# STM32F7x2 register map
File version: 1.3
CPU: CM7 r0p1, little endian, MPU, FPU, 4 interrupt priority bits
Registers are 32-bit, read-write, reset 0x0 unless marked. A register's access mark holds for its fields unless they carry their own. Offsets are from the block's base; [hi:lo] are bit positions; {n}, {i} and the like mark numbered series.

## STK — SysTick timer
Base 0xE000E010
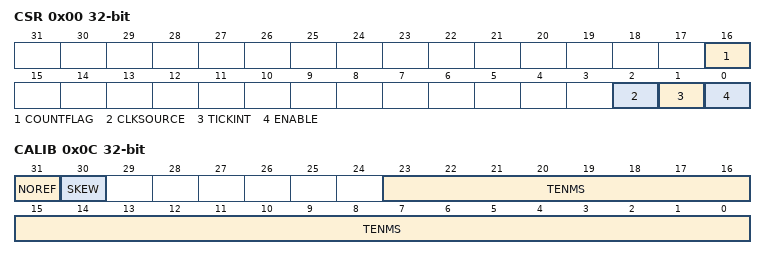
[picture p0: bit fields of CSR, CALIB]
0x00 CSR — SysTick control and status register
  [16] COUNTFLAG
  [2] CLKSOURCE — Clock source selection
  [1] TICKINT — SysTick exception request enable
  [0] ENABLE — Counter enable
0x04 RVR — SysTick reload value register
  [23:0] RELOAD — RELOAD value
0x08 CVR — SysTick current value register
  [23:0] CURRENT — Current counter value
0x0C CALIB — SysTick calibration value register
  [31] NOREF — NOREF flag. Reads as zero
  [30] SKEW — SKEW flag: Indicates whether the TENMS value is exact
  [23:0] TENMS — Calibration value

## NVIC_STIR — Nested vectored interrupt controller
Base 0xE000EF00
0x00 STIR — Software trigger interrupt register
  [8:0] INTID — Software generated interrupt ID

## FPU_CPACR — Floating point unit CPACR
Base 0xE000ED88
0x00 CPACR — Coprocessor access control register
  [23:20] CP

## SCB_ACTRL — System control block ACTLR
Base 0xE000E008
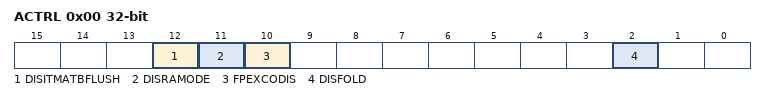
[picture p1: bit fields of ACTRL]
0x00 ACTRL — Auxiliary control register
  [12] DISITMATBFLUSH, [11] DISRAMODE, [10] FPEXCODIS, [2] DISFOLD

## FPU — Floting point unit
Base 0xE000EF34
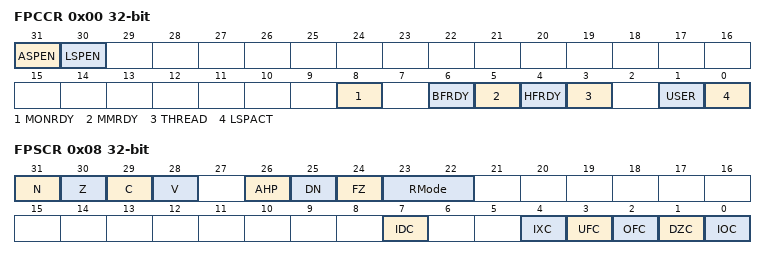
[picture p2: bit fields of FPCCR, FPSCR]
0x00 FPCCR — Floating-point context control register
  [31] ASPEN, [30] LSPEN, [8] MONRDY, [6] BFRDY, [5] MMRDY, [4] HFRDY, [3] THREAD, [1] USER, [0] LSPACT
0x04 FPCAR — Floating-point context address register
  [31:3] ADDRESS — Location of unpopulated floating-point
0x08 FPSCR — Floating-point status control register
  [31] N — Negative condition code flag
  [30] Z — Zero condition code flag
  [29] C — Carry condition code flag
  [28] V — Overflow condition code flag
  [26] AHP — Alternative half-precision control bit
  [25] DN — Default NaN mode control bit
  [24] FZ — Flush-to-zero mode control bit:
  [23:22] RMode — Rounding Mode control field
  [7] IDC — Input denormal cumulative exception bit.
  [4] IXC — Inexact cumulative exception bit
  [3] UFC — Underflow cumulative exception bit
  [2] OFC — Overflow cumulative exception bit
  [1] DZC — Division by zero cumulative exception bit.
  [0] IOC — Invalid operation cumulative exception bit

## PF — Processor features
Base 0xE000ED78
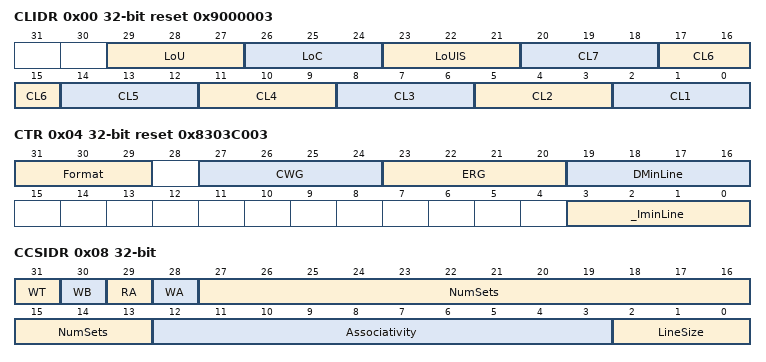
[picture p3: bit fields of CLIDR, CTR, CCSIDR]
0x00 CLIDR ro reset 0x9000003 — Cache Level ID register
  [29:27] LoU, [26:24] LoC, [23:21] LoUIS, [3n-1:3n-3] CL{n} (n=1..7)
0x04 CTR ro reset 0x8303C003 — Cache Type register
  [31:29] Format, [27:24] CWG, [23:20] ERG, [19:16] DMinLine, [3:0] _IminLine
0x08 CCSIDR ro — Cache Size ID register
  [31] WT, [30] WB, [29] RA, [28] WA, [27:13] NumSets, [12:3] Associativity, [2:0] LineSize

## AC — Access control
Base 0xE000EF90
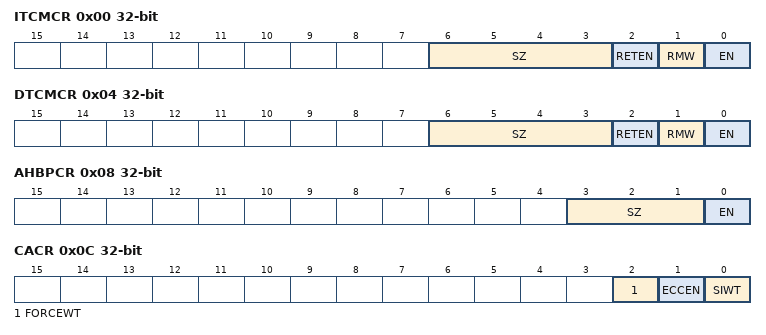
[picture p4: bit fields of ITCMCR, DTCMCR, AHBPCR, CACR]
0x00 ITCMCR — Instruction and Data Tightly-Coupled Memory Control Registers
  [6:3] SZ, [2] RETEN, [1] RMW, [0] EN
0x04 DTCMCR — Instruction and Data Tightly-Coupled Memory Control Registers
  [6:3] SZ, [2] RETEN, [1] RMW, [0] EN
0x08 AHBPCR — AHBP Control register
  [3:1] SZ, [0] EN
0x0C CACR — Auxiliary Cache Control register
  [2] FORCEWT, [1] ECCEN, [0] SIWT
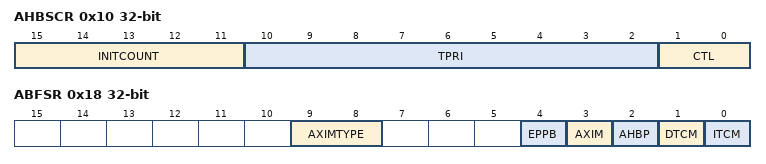
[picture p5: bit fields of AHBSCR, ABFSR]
0x10 AHBSCR — AHB Slave Control register
  [15:11] INITCOUNT, [10:2] TPRI, [1:0] CTL
0x18 ABFSR — Auxiliary Bus Fault Status register
  [9:8] AXIMTYPE, [4] EPPB, [3] AXIM, [2] AHBP, [1] DTCM, [0] ITCM

## AES — Advanced encryption standard hardware accelerator 1
Base 0x50060000
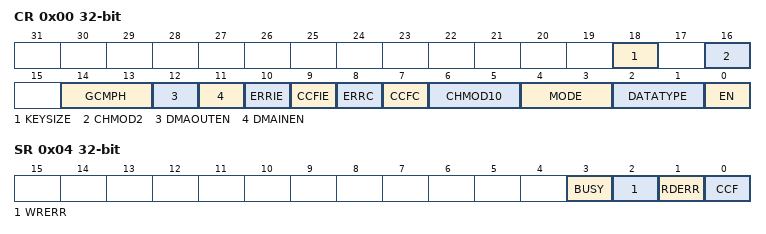
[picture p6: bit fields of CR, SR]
0x00 CR — control register
  [18] KEYSIZE — Key size selection
  [16] CHMOD2 — AES chaining mode Bit2
  [14:13] GCMPH — Used only for GCM, CCM and GMAC algorithms and has no effect when other algorithms are selected
  [12] DMAOUTEN — Enable DMA management of data output phase
  [11] DMAINEN — Enable DMA management of data input phase
  [10] ERRIE — Error interrupt enable
  [9] CCFIE — CCF flag interrupt enable
  [8] ERRC — Error clear
  [7] CCFC — Computation Complete Flag Clear
  [6:5] CHMOD10 — AES chaining mode Bit1 Bit0
  [4:3] MODE — AES operating mode
  [2:1] DATATYPE — Data type selection (for data in and data out to/from the cryptographic block)
  [0] EN — AES enable
0x04 SR ro — status register
  [3] BUSY — Busy flag
  [2] WRERR — Write error flag
  [1] RDERR — Read error flag
  [0] CCF — Computation complete flag
0x08 DINR — data input register
  [31:0] AES_DINR — Data Input Register
0x0C DOUTR ro — data output register
  [31:0] AES_DOUTR — Data output register
0x10 KEYR0 — key register 0
  [31:0] AES_KEYR0 — Data Output Register (LSB key [31:0])
0x14 KEYR1 — key register 1
  [31:0] AES_KEYR1 — AES key register (key [63:32])
0x18 KEYR2 — key register 2
  [31:0] AES_KEYR2 — AES key register (key [95:64])
0x1C KEYR3 — key register 3
  [31:0] AES_KEYR3 — AES key register (MSB key [127:96])
0x20 IVR0 — initialization vector register 0
  [31:0] AES_IVR0 — initialization vector register (LSB IVR [31:0])
0x24 IVR1 — initialization vector register 1
  [31:0] AES_IVR1 — Initialization Vector Register (IVR [63:32])
0x28 IVR2 — initialization vector register 2
  [31:0] AES_IVR2 — Initialization Vector Register (IVR [95:64])
0x2C IVR3 — initialization vector register 3
  [31:0] AES_IVR3 — Initialization Vector Register (MSB IVR [127:96])
{0x20+4i} KEYR{i} (i=4..7) — key register {i}
  [31:0] AES_KEYR{i} — AES key register (MSB key [{32i+31}:{32i}])
{0x40+4i} SUSP{i}R (i=0..7) — AES suspend register {i}
  [31:0] AES_SUSP{i}R

## USBPHYC — USBPHYC register interface
Base 0x40017C00
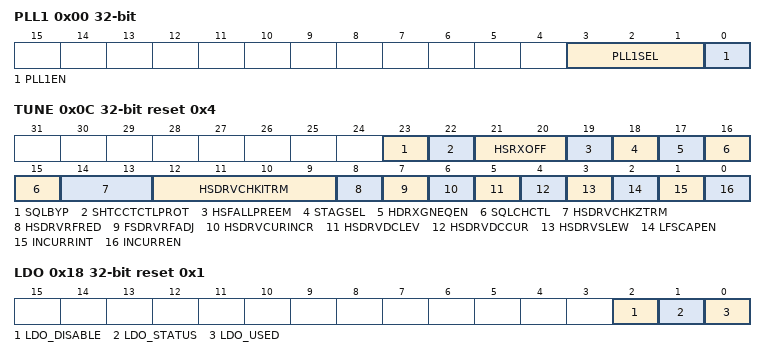
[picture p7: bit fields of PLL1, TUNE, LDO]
0x00 PLL1 — USBPHYC PLL1 control register
  [3:1] PLL1SEL — : Controls the PHY PLL1 input clock frequency selection
  [0] PLL1EN — Enable the PLL1 inside PHY
0x0C TUNE reset 0x4 — USBPHYC tuning control register
  [23] SQLBYP — This pin is used to bypass the squelch inter-locking circuitry
  [22] SHTCCTCTLPROT — Enables the short circuit protection circuitry in LS/FS driver
  [21:20] HSRXOFF — : HS Receiver Offset adjustment
  [19] HSFALLPREEM — HS Fall time control of single ended signals during pre-emphasis
  [18] STAGSEL — HS Tx staggering enable
  [17] HDRXGNEQEN — Enables the HS Rx Gain Equalizer
  [16:15] SQLCHCTL — Adjust the squelch DC threshold value
  [14:13] HSDRVCHKZTRM — Controls the PHY bus HS driver impedance tuning for choke compensation
  [12:9] HSDRVCHKITRM — HS Driver current trimming pins for choke compensation
  [8] HSDRVRFRED — High Speed rise-fall reduction enable
  [7] FSDRVRFADJ — Tuning pin to adjust the full speed rise/fall time
  [6] HSDRVCURINCR — Enable the HS driver current increase feature
  [5] HSDRVDCLEV — Increases the HS Driver DC level. Not applicable during the HS Test J and Test K data transfer
  [4] HSDRVDCCUR — Decreases the HS driver DC level
  [3] HSDRVSLEW — Controls the HS driver slew rate
  [2] LFSCAPEN — : Enables the Low Full Speed feedback capacitor
  [1] INCURRINT — Controls PHY current boosting
  [0] INCURREN — Controls the current boosting function
0x18 LDO access per field reset 0x1 — USBPHYC LDO control and status register
  [2] LDO_DISABLE rw — Controls disable of the High Speed PHY's LDO
  [1] LDO_STATUS ro — Monitors the status of the PHY's LDO
  [0] LDO_USED ro — Indicates the presence of the LDO in the chip
